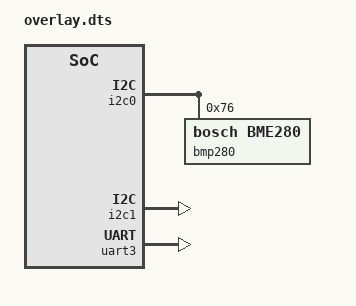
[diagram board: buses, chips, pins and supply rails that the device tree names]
/dts-v1/;
/plugin/;

/ {
	fragment@1 {
		target = <&i2c0>;
		__overlay__ {
			status = "okay";
			#size-cells = <0x00>;
			#address-cells = <0x01>;
			bmp280@76 {
				compatible = "bosch,bme280";
				status = "okay";
				reg = <0x76>;
			};
		};
	};

	fragment@2 {
		target = <&i2c1>;
		__overlay__ {
			status = "okay";
		};
	};

	fragment@3 {
		target = <&uart3>; /* /soc/serial@1c28c00 */
		__overlay__ {
			status = "okay";
			pinctrl-names = "default";
			pinctrl-0 = <&uart3_pins>;
		};
	};

};
